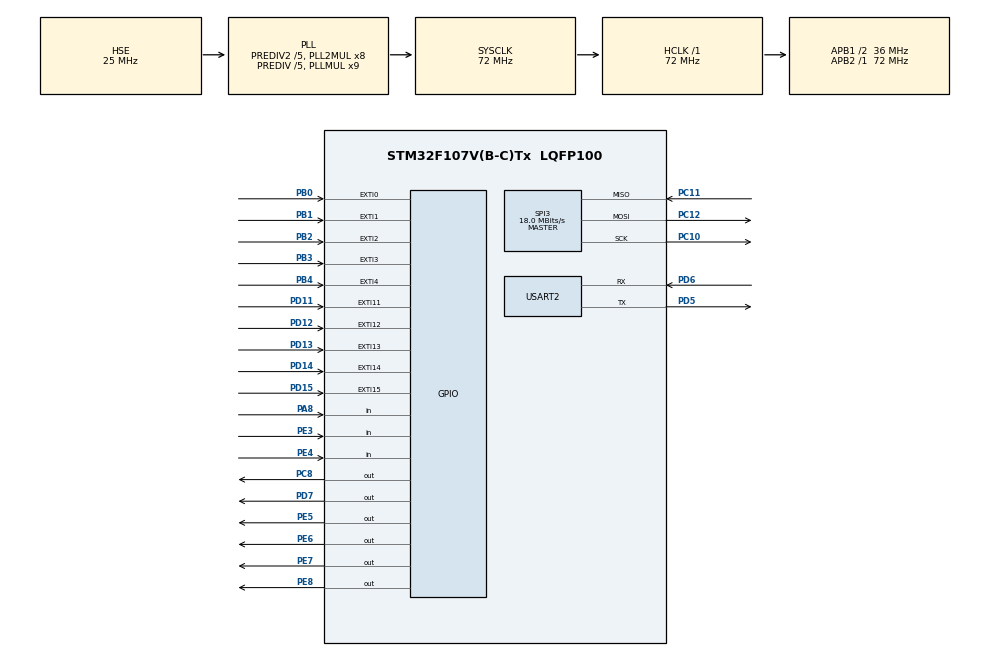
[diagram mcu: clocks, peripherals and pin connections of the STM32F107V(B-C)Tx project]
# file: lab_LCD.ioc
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Mcu.Family=STM32F1
Mcu.Name=STM32F107V(B-C)Tx
Mcu.Package=LQFP100
NVIC.EXTI0_IRQn=true\:0\:0\:false\:false\:true
NVIC.EXTI15_10_IRQn=true\:2\:0\:true\:false\:true
NVIC.EXTI1_IRQn=true\:0\:0\:false\:false\:true
NVIC.EXTI2_IRQn=true\:0\:0\:false\:false\:true
NVIC.EXTI3_IRQn=true\:0\:0\:false\:false\:true
NVIC.EXTI4_IRQn=true\:0\:0\:false\:false\:true
NVIC.PriorityGroup=NVIC_PRIORITYGROUP_2
NVIC.SPI3_IRQn=true\:2\:2\:true\:false\:true
NVIC.TIM1_UP_IRQn=true\:1\:0\:true\:false\:true
OSC_IN.Mode=HSE-External-Oscillator
OSC_IN.Signal=RCC_OSC_IN
OSC_OUT.Mode=HSE-External-Oscillator
OSC_OUT.Signal=RCC_OSC_OUT
PA8.Signal=GPIO_Input
PB0.Signal=GPXTI0
PB1.Signal=GPXTI1
PB2.Signal=GPXTI2
PB3.Signal=GPXTI3
PB4.Signal=GPXTI4
PC10.Mode=Full_Duplex_Master
PC10.Signal=SPI3_SCK
PC11.Mode=Full_Duplex_Master
PC11.Signal=SPI3_MISO
PC12.Mode=Full_Duplex_Master
PC12.Signal=SPI3_MOSI
PC8.Signal=GPIO_Output
PD11.Signal=GPXTI11
PD12.Signal=GPXTI12
PD13.Signal=GPXTI13
PD14.Signal=GPXTI14
PD15.Signal=GPXTI15
PD5.Mode=Asynchronous
PD5.Signal=USART2_TX
PD6.Mode=Asynchronous
PD6.Signal=USART2_RX
PD7.Signal=GPIO_Output
PE3.Signal=GPIO_Input
PE4.Signal=GPIO_Input
PE5.Signal=GPIO_Output
PE6.Signal=GPIO_Output
PE7.Signal=GPIO_Output
PE8.Signal=GPIO_Output
ProjectManager.HeapSize=0x200
ProjectManager.StackSize=0x400
ProjectManager.TargetToolchain=MDK-ARM V5
RCC.AHBFreq_Value=72000000
RCC.APB1CLKDivider=RCC_HCLK_DIV2
RCC.APB1Freq_Value=36000000
RCC.APB1TimFreq_Value=72000000
RCC.APB2Freq_Value=72000000
RCC.APB2TimFreq_Value=72000000
RCC.HCLKFreq_Value=72000000
RCC.HSEDivPLL=RCC_HSE_PREDIV_DIV5
RCC.HSE_VALUE=25000000
RCC.HSIState=RCC_HSI_ON
RCC.PLLMUL=RCC_PLL_MUL9
RCC.PLLSourceVirtual=RCC_PLLSOURCE_HSE
RCC.Prediv1Source=RCC_PREDIV1_SOURCE_PLL2
RCC.Prediv2=RCC_HSE_PREDIV2_DIV5
RCC.SYSCLKFreq_VALUE=72000000
RCC.SYSCLKSource=RCC_SYSCLKSOURCE_PLLCLK
RCC.USBFreq_Value=48000000
SPI3.CLKPhase=SPI_PHASE_1EDGE
SPI3.CLKPolarity=SPI_POLARITY_LOW
SPI3.CalculateBaudRate=18.0 MBits/s
SPI3.Mode=SPI_MODE_MASTER
VP_SYS_VS_ND.Mode=No_Debug
VP_TIM1_VS_ClockSourceINT.Mode=Internal
VP_TIM2_VS_ClockSourceINT.Mode=Internal
board=lab_LCD

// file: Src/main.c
/**
  ******************************************************************************
  * File Name          : main.c
  * Description        : Main program body
  ******************************************************************************
  *
  * COPYRIGHT(c) 2018 STMicroelectronics
  *
  * Redistribution and use in source and binary forms, with or without modification,
  * are permitted provided that the following conditions are met:
  *   1. Redistributions of source code must retain the above copyright notice,
  *      this list of conditions and the following disclaimer.
  *   2. Redistributions in binary form must reproduce the above copyright notice,
  *      this list of conditions and the following disclaimer in the documentation
  *      and/or other materials provided with the distribution.
  *   3. Neither the name of STMicroelectronics nor the names of its contributors
  *      may be used to endorse or promote products derived from this software
  *      without specific prior written permission.
  *
  * THIS SOFTWARE IS PROVIDED BY THE COPYRIGHT HOLDERS AND CONTRIBUTORS "AS IS"
  * AND ANY EXPRESS OR IMPLIED WARRANTIES, INCLUDING, BUT NOT LIMITED TO, THE
  * IMPLIED WARRANTIES OF MERCHANTABILITY AND FITNESS FOR A PARTICULAR PURPOSE ARE
  * DISCLAIMED. IN NO EVENT SHALL THE COPYRIGHT HOLDER OR CONTRIBUTORS BE LIABLE
  * FOR ANY DIRECT, INDIRECT, INCIDENTAL, SPECIAL, EXEMPLARY, OR CONSEQUENTIAL
  * DAMAGES (INCLUDING, BUT NOT LIMITED TO, PROCUREMENT OF SUBSTITUTE GOODS OR
  * SERVICES; LOSS OF USE, DATA, OR PROFITS; OR BUSINESS INTERRUPTION) HOWEVER
  * CAUSED AND ON ANY THEORY OF LIABILITY, WHETHER IN CONTRACT, STRICT LIABILITY,
  * OR TORT (INCLUDING NEGLIGENCE OR OTHERWISE) ARISING IN ANY WAY OUT OF THE USE
  * OF THIS SOFTWARE, EVEN IF ADVISED OF THE POSSIBILITY OF SUCH DAMAGE.
  *
  ******************************************************************************
  */
#include "main.h"
#include "stm32f1xx_hal.h"

/* USER CODE BEGIN Includes */

#include "et_stm32f_arm_kit_lcd.h"
#include <string.h>
#include <stdlib.h>
#include <time.h>
#include <stdbool.h>

/* USER CODE END Includes */

SPI_HandleTypeDef hspi3;

TIM_HandleTypeDef htim1;
TIM_HandleTypeDef htim2;

UART_HandleTypeDef huart2;

/* USER CODE BEGIN PV */
/* Private variables ---------------------------------------------------------*/
uint8_t posX;
uint16_t posY;
uint16_t i=10;
uint32_t count;
uint32_t sec;
uint32_t min;
uint16_t hue[20];

int isPress[5] = {0,0,0,0,0};
int score = 0;
int state = 0 ;
// state 0 : title
// state 1 : wait for Button Press
// state 2 : prerender background
// state 3 : gameplay
// state 4 : clear screen
// state 5 : gameover
int isDrawTitle = 0;
uint32_t timeshow[5] = {0,0,0,0,0};
uint32_t gametime = 59;
uint32_t temptimeshow[5] = {0,0,0,0,0};
int locationMole[3] = {0,1,2};
bool locationAvailable[5] = {false,false,false,false,false};
uint8_t locationX[5]= {80,80,160,160,160};
uint16_t locationY[5] = {109,218,80,160,240};
int mole[5] ={0,0,0};
char str[20];
/* USER CODE END PV */

void SystemClock_Config(void);
void Error_Handler(void);
static void MX_GPIO_Init(void);
static void MX_SPI3_Init(void);
static void MX_USART2_UART_Init(void);
static void MX_TIM2_Init(void);
static void MX_TIM1_Init(void);

/* USER CODE BEGIN PFP */
/* Private function prototypes -----------------------------------------------*/

char pos[50];
uint32_t count;
uint32_t sec;
uint32_t min;
uint16_t fox[13][15] = {
    {0xFFFF,0xFFFF,0xFFFF,0x0000,0xFFFF,0xFFFF,0xFFFF,0xFFFF,0xFFFF,0xFFFF,0xFFFF,0x0000,0xFFFF,0xFFFF,0xFFFF},
    {0xFFFF,0xFFFF,0x0000,0xFFFF,0x0000,0xFFFF,0xFFFF,0xFFFF,0xFFFF,0xFFFF,0x0000,0xFFFF,0x0000,0xFFFF,0xFFFF},
  	{0xFFFF,0xFFFF,0x0000,0xFFFF,0xF3C0,0x0000,0xFFFF,0xFFFF,0xFFFF,0x0000,0xF3C0,0xFFFF,0x0000,0xFFFF,0xFFFF},
		{0xFFFF,0xFFFF,0x0000,0xFFFF,0xF3C0,0xF3C0,0x0000,0x0000,0x0000,0xF3C0,0xF3C0,0xFFFF,0x0000,0xFFFF,0xFFFF},
		{0xFFFF,0xFFFF,0x0000,0xFFFF,0x0000,0x0000,0xF3C0,0xF3C0,0xF3C0,0x0000,0x0000,0xFFFF,0x0000,0xFFFF,0xFFFF},
		{0xFFFF,0xFFFF,0x0000,0x0000,0xF3C0,0xF3C0,0xF3C0,0xF3C0,0xF3C0,0xF3C0,0xF3C0,0x0000,0x0000,0xFFFF,0xFFFF},
		{0xFFFF,0xFFFF,0x0000,0xF3C0,0xF3C0,0xF3C0,0xF3C0,0xF3C0,0xF3C0,0xF3C0,0xF3C0,0xF3C0,0x0000,0xFFFF,0xFFFF},
		{0xFFFF,0xFFFF,0x0000,0xF3C0,0x0000,0xF3C0,0xF3C0,0xF3C0,0xF3C0,0xF3C0,0x0000,0xF3C0,0x0000,0xFFFF,0xFFFF},
		{0xFFFF,0x0000,0xF3C0,0xF3C0,0x0000,0xF3C0,0x0000,0x0000,0x0000,0xF3C0,0x0000,0xF3C0,0xF3C0,0x0000,0xFFFF},
		{0xFFFF,0x0000,0xF3C0,0xF3C0,0xF3C0,0xF3C0,0xFFFF,0x0000,0xFFFF,0xF3C0,0xF3C0,0xF3C0,0xF3C0,0x0000,0xFFFF},
		{0x0000,0xF3C0,0xF3C0,0xF3C0,0xF3C0,0xFFFF,0xFFFF,0xFFFF,0xFFFF,0xFFFF,0xF3C0,0xF3C0,0xF3C0,0xF3C0,0x0000},
		{0xFFFF,0x0000,0x0000,0xFFFF,0xFFFF,0xFFFF,0xFFFF,0xFFFF,0xFFFF,0xFFFF,0xFFFF,0xFFFF,0x0000,0x0000,0xFFFF},
	  {0xFFFF,0xFFFF,0xFFFF,0x0000,0x0000,0x0000,0x0000,0x0000,0x0000,0x0000,0x0000,0x0000,0xFFFF,0xFFFF,0xFFFF}
};

uint16_t molepic[15][15] = {
    { 0x6223,0x0000,0x0000,0x0000,0x0000,0x0000,0x0000,0x0000,0x0000,0x0000,0x0000,0x0000,0x0000,0x0000,0x6223 },
    { 0x0000,0xBBEB,0x0000,0x0000,0x0000,0xBBEB,0xBBEB,0xBBEB,0xBBEB,0xBBEB,0x0000,0x0000,0x0000,0xBBEB,0x0000 },
    { 0x0000,0x0000,0x0000,0xBBEB,0xBBEB,0xBBEB,0xBBEB,0xBBEB,0xBBEB,0xBBEB,0xBBEB,0xBBEB,0x0000,0x0000,0x0000 },
    { 0x0000,0x0000,0xBBEB,0xBBEB,0xBBEB,0xBBEB,0xBBEB,0xBBEB,0xBBEB,0xBBEB,0xBBEB,0xBBEB,0xBBEB,0x0000,0x0000 },
    { 0x0000,0x0000,0xBBEB,0xBBEB,0xBBEB,0xBBEB,0xBBEB,0xBBEB,0xBBEB,0xBBEB,0xBBEB,0xBBEB,0xBBEB,0x0000,0x0000 },
    { 0x0000,0xBBEB,0x0000,0xBBEB,0xBBEB,0xBBEB,0xBBEB,0xBBEB,0xBBEB,0xBBEB,0xBBEB,0xBBEB,0x0000,0xBBEB,0x0000 },
    { 0x0000,0xBBEB,0x0000,0x0000,0xBBEB,0xBBEB,0x0000,0x0000,0x0000,0xBBEB,0xBBEB,0x0000,0x0000,0xBBEB,0x0000 },
    { 0x0000,0xBBEB,0xBBEB,0xBBEB,0xBBEB,0xBBEB,0xBBEB,0x0000,0xBBEB,0xBBEB,0xBBEB,0xBBEB,0xBBEB,0xBBEB,0x0000 },
    { 0x0000,0xBBEB,0xBBEB,0xBBEB,0xBBEB,0xBBEB,0x0000,0xBBEB,0x0000,0xBBEB,0xBBEB,0xBBEB,0xBBEB,0xBBEB,0x0000 },
    { 0x0000,0xBBEB,0xBBEB,0xBBEB,0xBBEB,0x0000,0xBBEB,0xBBEB,0xBBEB,0x0000,0xBBEB,0xBBEB,0xBBEB,0xBBEB,0x0000 },
    { 0x0000,0x0000,0xBBEB,0xBBEB,0xBBEB,0xBBEB,0xBBEB,0xBBEB,0xBBEB,0xBBEB,0xBBEB,0xBBEB,0xBBEB,0x0000,0x0000 },
    { 0x0000,0x0000,0xBBEB,0xBBEB,0xBBEB,0xBBEB,0x0000,0x0000,0x0000,0xBBEB,0xBBEB,0xBBEB,0xBBEB,0x0000,0x0000 },
    { 0x0000,0x0000,0x0000,0xBBEB,0xBBEB,0x0000,0xE5F2,0xE5F2,0xE5F2,0x0000,0xBBEB,0xBBEB,0x0000,0x0000,0x0000 },
    { 0x0000,0x0000,0xBBEB,0x0000,0x0000,0xE5F2,0xE5F2,0xE5F2,0xE5F2,0xE5F2,0x0000,0x0000,0xBBEB,0x0000,0x0000 },
    { 0x6223,0x0000,0x0000,0x0000,0x0000,0x0000,0x0000,0x0000,0x0000,0x0000,0x0000,0x0000,0x0000,0x0000,0x6223 }  };
uint16_t title[16][32] ={
	{0x0000, 0x0000, 0x0000, 0x0000, 0x0000, 0x0000, 0x0000, 0x0000, 0x0000, 0x0000, 0x0000, 0x0000, 0x0000, 0x0000, 0x0000, 0x0000, 0x0000, 0x0000, 0x0000, 0x0000, 0x0000, 0x0000, 0x0000, 0x0000, 0x0000, 0x0000, 0x0000, 0x0000, 0x0000, 0x0000, 0x0000, 0x0000},
	{0x0000, 0x0000, 0x0000, 0x0000, 0x0000, 0x0000, 0x0000, 0x0000, 0x0000, 0x0000, 0x0000, 0x0000, 0x0000, 0x0000, 0x0000, 0x0000, 0x0000, 0x0000, 0x0000, 0x0000, 0x0000, 0x0000, 0x0000, 0x0000, 0x0000, 0x0000, 0x0000, 0x0000, 0x0000, 0x0000, 0x0000, 0x0000},
	{0x0000, 0x0000, 0x0000, 0x0000, 0x0000, 0x0000, 0x0000, 0x0000, 0x7205, 0x0000, 0x0000, 0x0000, 0x7205, 0x0000, 0xFC26, 0x0000, 0x0000, 0xFC26, 0x0000, 0x7205, 0x7205, 0x7205, 0x7205, 0x0000, 0xFC26, 0xFC26, 0xFC26, 0xFC26, 0x0000, 0x0000, 0x0000, 0x0000},
	{0x0000, 0x0000, 0x0000, 0x0000, 0x0000, 0x0000, 0x0000, 0x0000, 0x7205, 0x0000, 0x0000, 0x0000, 0x7205, 0x0000, 0xFC26, 0x0000, 0x0000, 0xFC26, 0x0000, 0x7205, 0x0000, 0x0000, 0x7205, 0x0000, 0xFC26, 0x0000, 0x0000,  0xFC26, 0x0000, 0x0000, 0x0000, 0x0000},
	{0x0000, 0x0000, 0x0000, 0x0000, 0x0000, 0x0000, 0x0000, 0x0000, 0x7205, 0x0000, 0x7205, 0x0000, 0x7205, 0x0000, 0xFC26, 0xFC26, 0xFC26, 0xFC26, 0x0000, 0x7205, 0x7205,  0x7205, 0x7205, 0x0000, 0xFC26, 0x0000, 0x0000,0x0000, 0x0000, 0x0000, 0x0000, 0x0000},
	{0x0000, 0x0000, 0x0000, 0x0000, 0xFFFF, 0xFFFF, 0x0000, 0x0000, 0x7205, 0x7205, 0x7205, 0x7205, 0x7205, 0x0000, 0xFC26, 0x0000, 0x0000, 0xFC26, 0x0000, 0x7205, 0x0000, 0x0000, 0x7205, 0x0000, 0xFC26, 0x0000, 0x0000, 0xFC26, 0x0000, 0x0000, 0x0000, 0x0000},
	{0x0000, 0x0000, 0x0000, 0xFFFF, 0x0000, 0x0000, 0xFFFF, 0x0000, 0x7205, 0x7205, 0x0000, 0x7205, 0x7205, 0x0000, 0xFC26, 0x0000, 0x0000, 0x0000, 0x0000, 0x0000, 0x0000, 0x0000, 0x7205, 0x0000, 0xFC26, 0xFC26, 0xFC26, 0xFC26, 0x0000, 0x0000, 0x0000, 0x0000},
	{0x0000, 0x0000, 0x0000, 0xFFFF, 0xFFFF, 0xFFFF, 0xFFFF, 0x0000, 0x0000, 0x0000, 0x0000, 0x0000, 0x0000, 0x0000, 0xBBEB, 0x0000, 0x0000, 0x0000, 0x0000, 0x0000, 0xBBEB, 0x0000, 0x7205, 0x0000, 0x0000, 0x0000, 0x0000, 0x0000, 0x0000, 0x0000, 0x0000, 0x0000},
	{0x0000, 0x0000, 0x0000, 0xFFFF, 0x0000, 0x0000, 0xFFFF, 0x0000, 0xFE22, 0xFE22, 0x0000, 0xFE22, 0xFE22, 0x0000, 0x0000, 0xBBEB, 0xBBEB, 0xBBEB, 0xBBEB, 0xBBEB, 0x0000, 0x0000, 0x7205, 0x0000, 0x0000, 0x7205, 0x7205, 0x7205, 0x0000, 0x0000, 0x0000, 0x0000},
	{0x0000, 0x0000, 0x0000, 0x0000, 0x0000, 0x0000, 0x0000, 0x0000, 0xFE22, 0xFE22, 0x0000, 0xFE22, 0xFE22, 0x0000, 0xBBEB, 0xBBEB, 0xBBEB, 0xBBEB, 0xBBEB, 0xBBEB, 0xBBEB, 0x0000, 0x7205, 0x0000, 0x0000, 0x7205, 0x0000, 0x0000, 0x0000, 0x0000, 0x0000, 0x0000},
  {0x0000, 0x0000, 0x0000, 0x0000, 0x0000, 0x0000, 0x0000, 0x0000, 0xFE22, 0x0000, 0xFE22, 0x0000, 0xFE22, 0x0000, 0xBBEB, 0xBBEB, 0xBBEB, 0xBBEB, 0xBBEB, 0xBBEB, 0xBBEB, 0x0000, 0x7205, 0x0000, 0x0000, 0x7205, 0x7205, 0x7205, 0x0000, 0x0000, 0x0000, 0x0000},
	{0x0000, 0x0000, 0x0000, 0x0000, 0x0000, 0x0000, 0x0000, 0x0000, 0xFE22, 0x0000, 0x0000, 0x0000, 0xFE22, 0x0000, 0xBBEB, 0x0000, 0xBBEB, 0xBBEB, 0xBBEB, 0x0000, 0xBBEB, 0x0000, 0x7205, 0x0000, 0x0000, 0x7205, 0x0000, 0x0000, 0x0000, 0x0000, 0x0000, 0x0000},
	{0x0000, 0x0000, 0x0000, 0x0000, 0x0000, 0x0000, 0x0000, 0x0000, 0xFE22, 0x0000, 0x0000, 0x0000, 0xFE22, 0x0000, 0xBBEB, 0xBBEB, 0xBBEB, 0xBBEB, 0xBBEB, 0xBBEB, 0xBBEB, 0x0000, 0x7205, 0x7205, 0x7205, 0x7205, 0x7205, 0x7205, 0x0000, 0x0000, 0x0000, 0x0000},
	{0x0000, 0x0000, 0x0000, 0x0000, 0x0000, 0x0000, 0x0000, 0x0000, 0x0000, 0x0000, 0x0000, 0x0000, 0x0000, 0x0000, 0xBBEB, 0xBBEB, 0xBBEB, 0x0000, 0xBBEB, 0xBBEB, 0xBBEB, 0x0000, 0x0000, 0x0000, 0x0000, 0x0000, 0x0000, 0x0000, 0x0000, 0x0000, 0x0000, 0x0000},
  {0x0000, 0x0000, 0x0000, 0x0000, 0x0000, 0x0000, 0x0000, 0x0000, 0x0000, 0x0000, 0x0000, 0x0000, 0x0000, 0x0000, 0x0000, 0xBBEB, 0x0000, 0xE5F2, 0x0000, 0xBBEB, 0x0000, 0x0000, 0x0000, 0x0000, 0x0000, 0x0000, 0x0000, 0x0000, 0x0000, 0x0000, 0x0000, 0x0000},
	{0x0000, 0x0000, 0x0000, 0x0000, 0x0000, 0x0000, 0x0000, 0x0000, 0x0000, 0x0000, 0x0000, 0x0000, 0x0000, 0x0000, 0xBBEB, 0x0000, 0x0000, 0x0000, 0x0000, 0x0000, 0xBBEB, 0x0000, 0x0000, 0x0000, 0x0000, 0x0000, 0x0000, 0x0000, 0x0000, 0x0000, 0x0000, 0x0000},

};
uint16_t moleDie[15][15] = {
{0x0000, 0x0000, 0x0000, 0x0000, 0x0000, 0xFFFF, 0xFFFF, 0x0000, 0xFFFF, 0xFFFF, 0x0000, 0x0000, 0x0000, 0x0000, 0x0000},
{0x0000, 0xBBEB, 0x0000, 0x0000, 0x0000, 0xBBEB, 0xFFFF, 0xFFFF, 0xFFFF, 0xBBEB, 0x0000, 0x0000, 0x0000, 0xBBEB, 0x0000},
{0x0000, 0x0000, 0x0000, 0xBBEB, 0xBBEB, 0xBBEB, 0xBBEB, 0xFFFF, 0xBBEB, 0xBBEB, 0xBBEB, 0xBBEB, 0x0000, 0x0000, 0x0000},
{0x0000, 0x0000, 0xBBEB, 0xBBEB, 0xBBEB, 0xBBEB, 0xFFFF, 0xFFFF, 0xFFFF, 0xBBEB, 0xBBEB, 0xBBEB, 0xBBEB, 0x0000, 0x0000},
{0x0000, 0x0000, 0xBBEB, 0xBBEB, 0xBBEB, 0xFFFF, 0xFFFF, 0xBBEB, 0xFFFF, 0xFFFF, 0xBBEB, 0xBBEB, 0xBBEB, 0x0000, 0x0000},
{0x0000, 0xBBEB, 0x0000, 0xBBEB, 0x0000, 0xBBEB, 0xBBEB, 0xBBEB, 0xBBEB, 0xBBEB, 0x0000, 0xBBEB, 0x0000, 0xBBEB, 0x0000},
{0x0000, 0xBBEB, 0xBBEB, 0x0000, 0xBBEB, 0xBBEB, 0x0000, 0x0000, 0x0000, 0xBBEB, 0xBBEB, 0x0000, 0xBBEB, 0xBBEB, 0x0000},
{0x0000, 0xBBEB, 0x0000, 0x46DF, 0x0000, 0xBBEB, 0xBBEB, 0x0000, 0xBBEB, 0xBBEB, 0x0000, 0x46DF, 0x0000, 0xBBEB, 0x0000},
{0x0000, 0xBBEB, 0xBBEB, 0x46DF, 0xBBEB, 0xBBEB, 0x0000, 0xF57F, 0x0000, 0xBBEB, 0xBBEB, 0x46DF, 0xBBEB, 0xBBEB, 0x0000},
{0x0000, 0xBBEB, 0xBBEB, 0x46DF, 0xBBEB, 0xBBEB, 0x0000, 0x0000, 0x0000, 0xBBEB, 0xBBEB, 0x46DF, 0xBBEB, 0xBBEB, 0x0000},
{0x0000, 0x0000, 0xBBEB, 0x46DF, 0xBBEB, 0xBBEB, 0xBBEB, 0xBBEB, 0xBBEB, 0xBBEB, 0xBBEB, 0x46DF, 0xBBEB, 0x0000, 0x0000},
{0x0000, 0x0000, 0xBBEB, 0x46DF, 0xBBEB, 0xBBEB, 0x0000, 0x0000, 0x0000, 0xBBEB, 0xBBEB, 0x46DF, 0xBBEB, 0x0000, 0x0000},
{0x0000, 0xBBEB, 0x0000, 0x46DF, 0xBBEB, 0x0000, 0xE5F2, 0xE5F2, 0xE5F2, 0x0000, 0xBBEB, 0x46DF, 0x0000, 0xBBEB, 0x0000},
{0x0000, 0x0000, 0x0000, 0x0000, 0x0000, 0xE5F2, 0xE5F2, 0xE5F2, 0xE5F2, 0xE5F2, 0x0000, 0x0000, 0x0000, 0x0000, 0x0000},
{0x0000, 0x0000, 0x0000, 0x0000, 0x0000, 0x0000, 0x0000, 0x0000, 0x0000, 0x0000, 0x0000, 0x0000, 0x0000, 0x0000, 0x0000}
};

uint16_t background[48][64] = {
{0x6223,0x6223, 0x6223,0x6223, 0x6223,0x6223, 0x6223,0x6223, 0x6223,0x6223, 0x6223,0x6223, 0x6223,0x6223, 0x6223,0x6223, 0x6223,0x6223, 0x6223,0x6223, 0x6223,0x6223, 0x6223,0x6223, 0x6223,0x6223, 0x6223,0x6223, 0x6223,0x6223, 0x6223,0x6223, 0x6223,0x6223, 0x6223,0x6223, 0x6223,0x6223, 0x6223,0x6223, 0x6223,0x6223, 0x6223,0x6223, 0x6223,0x6223, 0x6223,0x6223, 0x6223,0x6223, 0x6223,0x6223, 0x6223,0x6223, 0x6223,0x6223, 0x6223,0xB668, 0xB668,0x6223, 0x6223,0x6223, 0xB668,0xB668},
{0x6223,0x6223, 0x6223,0x6223, 0x6223,0x6223, 0x6223,0xB668, 0xB668,0x6223, 0x6223,0x6223, 0x6223,0x6223, 0xB668,0x6223, 0x6223,0x6223, 0x6223,0x8327, 0x6223,0x6223, 0x6223,0x6223, 0x6223,0x6223, 0x6223,0x6223, 0x6223,0x6223, 0x6223,0x6223, 0x6223,0x6223, 0x6223,0x6223, 0x6223,0x6223, 0x6223,0x6223, 0x6223,0x6223, 0x6223,0x6223, 0x6223,0x6223, 0x6223,0x6223, 0x6223,0x6223, 0x6223,0x6223, 0x6223,0x6223, 0x6223,0x6223, 0x6223,0xB668, 0xB668,0xB668, 0xB668,0xB668, 0xB668,0x6223},
{0x6223,0x6223, 0x6223,0x6223, 0x6223,0x6223, 0x6223,0xB668, 0xB668,0xB668, 0x6223,0x6223, 0x6223,0xB668, 0xB668,0x6223, 0x6223,0x6223, 0x6223,0x6223, 0x6223,0x6223, 0x6223,0x6223, 0x6223,0x6223, 0x6223,0x6223, 0x6223,0x6223, 0x6223,0x6223, 0x6223,0x6223, 0x6223,0x6223, 0x6223,0x6223, 0x6223,0x6223, 0x6223,0x6223, 0x6223,0x6223, 0x6223,0x6223, 0x6223,0x6223, 0x6223,0x6223, 0x6223,0x6223, 0x6223,0x6223, 0x6223,0x6223, 0x6223,0x6223, 0x6223,0x6223, 0xB668,0x6223, 0x6223,0x6223},
{0x6223,0x8327, 0x6223,0x6223, 0x6223,0x6223, 0x6223,0x6223, 0x6223,0xB668, 0xB668,0xB668, 0xB668,0xB668, 0x6223,0x6223, 0x6223,0x6223, 0x6223,0x6223, 0x6223,0x6223, 0x6223,0x6223, 0x6223,0x6223, 0x6223,0x6223, 0x6223,0x6223, 0x6223,0x6223, 0x6223,0x6223, 0x6223,0x6223, 0x6223,0x6223, 0x6223,0x6223, 0x6223,0x6223, 0x6223,0x6223, 0x6223,0x6223, 0x8327,0x6223, 0x6223,0x6223, 0x6223,0x6223, 0x6223,0x6223, 0x6223,0x6223, 0x6223,0x6223, 0x6223,0x6223, 0x6223,0x6223, 0x6223,0x6223},
{0x6223,0x6223, 0x6223,0x6223, 0x6223,0x6223, 0x6223,0x6223, 0x6223,0x6223, 0xB668,0xB668, 0x6223,0x6223, 0x6223,0x6223, 0x6223,0x6223, 0x6223,0x6223, 0x6223,0x6223, 0x6223,0x6223, 0x6223,0x6223, 0x6223,0x6223, 0x6223,0x6223, 0x6223,0x6223, 0x6223,0x6223, 0x6223,0x6223, 0x6223,0x6223, 0x6223,0x6223, 0x6223,0x6223, 0x6223,0x6223, 0x6223,0x6223, 0x6223,0x6223, 0x6223,0x6223, 0x6223,0x6223, 0x6223,0x6223, 0x6223,0x6223, 0x6223,0x6223, 0x6223,0x6223, 0x6223,0x6223, 0x6223,0x6223},
{0x6223,0x6223, 0x6223,0x6223, 0x6223,0x6223, 0x6223,0x6223, 0x6223,0x6223, 0x6223,0x6223, 0x6223,0x6223, 0x6223,0x6223, 0x6223,0x6223, 0x6223,0x6223, 0x6223,0x6223, 0x6223,0x6223, 0x6223,0x6223, 0x6223,0x6223, 0x6223,0x6223, 0x6223,0x6223, 0x6223,0x6223, 0x6223,0x6223, 0x6223,0x6223, 0x6223,0x6223, 0x6223,0x6223, 0x6223,0x6223, 0x6223,0x6223, 0x6223,0x6223, 0x6223,0x6223, 0x6223,0x6223, 0x6223,0x6223, 0x6223,0x6223, 0x6223,0x6223, 0x6223,0x6223, 0x6223,0x6223, 0x6223,0x6223},
{0x6223,0x6223, 0x6223,0x6223, 0x6223,0x6223, 0x6223,0x6223, 0x6223,0x6223, 0x6223,0x6223, 0x6223,0x6223, 0x6223,0x6223, 0x6223,0x6223, 0x6223,0x6223, 0x6223,0x6223, 0x6223,0x6223, 0x6223,0x6223, 0x6223,0x6223, 0x6223,0x6223, 0x6223,0x6223, 0x6223,0x6223, 0x6223,0x6223, 0x6223,0x6223, 0x6223,0x6223, 0x6223,0x6223, 0x6223,0x6223, 0x6223,0x6223, 0x6223,0x6223, 0x6223,0x6223, 0x6223,0x6223, 0x6223,0x6223, 0x6223,0x6223, 0x6223,0x6223, 0x6223,0x6223, 0x6223,0x6223, 0x6223,0x6223},
{0x6223,0x6223, 0x6223,0x6223, 0x6223,0x6223, 0x6223,0x6223, 0x6223,0x6223, 0x6223,0x6223, 0x6223,0x6223, 0x6223,0x6223, 0x6223,0x6223, 0x6223,0x6223, 0x6223,0x6223, 0x6223,0x6223, 0x6223,0x6223, 0x6223,0x6223, 0x6223,0x6223, 0x6223,0x6223, 0x6223,0x6223, 0x6223,0x6223, 0x6223,0x6223, 0x6223,0x6223, 0x6223,0x6223, 0x6223,0x6223, 0x6223,0x6223, 0x6223,0x6223, 0x6223,0x6223, 0x6223,0x6223, 0x6223,0x6223, 0x6223,0x6223, 0x6223,0x6223, 0x6223,0x6223, 0x6223,0x6223, 0x6223,0x6223},
{0x6223,0x6223, 0x6223,0x6223, 0x6223,0x6223, 0x6223,0x6223, 0x6223,0x6223, 0x6223,0x6223, 0x6223,0x6223, 0x6223,0x6223, 0x8327,0x6223, 0x6223,0x6223, 0x6223,0x6223, 0x6223,0x6223, 0x6223,0x6223, 0x6223,0x6223, 0x6223,0x6223, 0x6223,0x6223, 0x6223,0x6223, 0x6223,0x6223, 0x6223,0x6223, 0x6223,0x6223, 0x6223,0x6223, 0x6223,0x6223, 0x6223,0x6223, 0x6223,0x6223, 0x6223,0x6223, 0x6223,0x6223, 0x6223,0x6223, 0x6223,0x6223, 0x6223,0x6223, 0x6223,0x6223, 0x6223,0x6223, 0x6223,0x6223},
{0x6223,0x6223, 0x6223,0x6223, 0x6223,0x6223, 0x6223,0x6223, 0x6223,0x6223, 0x6223,0x6223, 0x6223,0x6223, 0x6223,0x6223, 0x6223,0x6223, 0x6223,0x6223, 0x6223,0x6223, 0x6223,0x6223, 0x6223,0x6223, 0x6223,0x6223, 0x6223,0x6223, 0x6223,0x6223, 0x6223,0x6223, 0x6223,0x6223, 0x6223,0x6223, 0x6223,0x6223, 0x6223,0x6223, 0x6223,0x6223, 0x6223,0x6223, 0x6223,0x6223, 0x6223,0x6223, 0x6223,0x6223, 0x6223,0x6223, 0x6223,0x6223, 0x6223,0x6223, 0x6223,0x6223, 0x6223,0x6223, 0x6223,0x6223},
{0x6223,0x6223, 0x6223,0x6223, 0x6223,0x6223, 0x6223,0x6223, 0x6223,0x6223, 0x6223,0x6223, 0x6223,0x6223, 0x6223,0x6223, 0x6223,0x6223, 0x6223,0x6223, 0x6223,0x6223, 0x6223,0x6223, 0x6223,0x6223, 0x6223,0x6223, 0x6223,0x6223, 0x6223,0x6223, 0x6223,0x6223, 0x6223,0x6223, 0x6223,0x6223, 0x6223,0x6223, 0x6223,0x6223, 0x6223,0x6223, 0x6223,0x6223, 0x6223,0x6223, 0x8327,0x6223, 0x6223,0x6223, 0x6223,0x6223, 0x6223,0x6223, 0x6223,0x6223, 0x6223,0x6223, 0x6223,0x6223, 0x6223,0x6223},
{0x6223,0x6223, 0x8327,0x6223, 0x6223,0x6223, 0x6223,0x6223, 0x6223,0x6223, 0x6223,0x6223, 0x6223,0x6223, 0x6223,0x6223, 0x6223,0x6223, 0x6223,0x6223, 0x6223,0x6223, 0x6223,0x6223, 0x6223,0x6223, 0x6223,0x6223, 0x6223,0x6223, 0x6223,0x6223, 0x6223,0x6223, 0x6223,0x6223, 0x6223,0x6223, 0x6223,0x6223, 0x6223,0x6223, 0x6223,0x6223, 0x6223,0x6223, 0x6223,0x6223, 0x6223,0x6223, 0x6223,0x6223, 0x6223,0x6223, 0x6223,0x6223, 0x6223,0x6223, 0x6223,0x6223, 0x6223,0x6223, 0x6223,0x6223},
{0x6223,0x6223, 0x6223,0x6223, 0x6223,0x6223, 0x6223,0x6223, 0x6223,0x6223, 0x6223,0x6223, 0x6223,0x6223, 0x6223,0x6223, 0x6223,0x6223, 0x6223,0x6223, 0x6223,0x6223, 0x6223,0x6223, 0x6223,0x6223, 0x6223,0x6223, 0x6223,0x6223, 0x6223,0x6223, 0x6223,0x6223, 0x6223,0x6223, 0x6223,0x6223, 0x6223,0x6223, 0x6223,0x6223, 0x6223,0x6223, 0x6223,0x6223, 0x6223,0x6223, 0x6223,0x6223, 0x6223,0x6223, 0x6223,0x6223, 0x6223,0x6223, 0x6223,0x6223, 0x6223,0x6223, 0x6223,0x6223, 0x6223,0x6223},
{0x6223,0x6223, 0x6223,0x6223, 0x6223,0x6223, 0x6223,0x6223, 0x6223,0x6223, 0x6223,0x6223, 0x6223,0x6223, 0x6223,0x6223, 0x6223,0x6223, 0x6223,0x6223, 0x6223,0x6223, 0x6223,0x6223, 0x6223,0x6223, 0x6223,0x6223, 0x6223,0x6223, 0x6223,0x6223, 0x6223,0x6223, 0x6223,0x6223, 0x6223,0x8327, 0x6223,0x6223, 0x6223,0x6223, 0x6223,0x6223, 0x6223,0x6223, 0x6223,0x6223, 0x6223,0x6223, 0x6223,0x6223, 0x6223,0x6223, 0x6223,0x6223, 0x6223,0x6223, 0x6223,0x6223, 0x6223,0x6223, 0x6223,0x6223},
{0x6223,0x6223, 0x6223,0x6223, 0x6223,0x6223, 0x6223,0x6223, 0x6223,0x6223, 0x6223,0x6223, 0x6223,0x6223, 0x6223,0x6223, 0x6223,0x6223, 0x6223,0x6223, 0x6223,0x6223, 0x6223,0x6223, 0x6223,0x6223, 0x6223,0x6223, 0x6223,0x6223, 0x6223,0x6223, 0x6223,0x6223, 0x6223,0x6223, 0x6223,0x6223, 0x6223,0x6223, 0x6223,0x6223, 0x6223,0x6223, 0x6223,0x6223, 0x6223,0x6223, 0x6223,0x6223, 0x6223,0x6223, 0x6223,0x6223, 0x6223,0x6223, 0x6223,0x6223, 0x6223,0x6223, 0x6223,0x6223, 0x6223,0x6223},
{0x6223,0x6223, 0x6223,0x6223, 0x6223,0x6223, 0x6223,0x6223, 0x6223,0x6223, 0x6223,0x6223, 0x6223,0x6223, 0x6223,0x6223, 0x6223,0x6223, 0x6223,0x6223, 0x6223,0x6223, 0x6223,0x6223, 0x6223,0x6223, 0x6223,0x6223, 0x6223,0x6223, 0x6223,0x6223, 0x6223,0x6223, 0x6223,0x6223, 0x6223,0x6223, 0x6223,0x6223, 0x6223,0x6223, 0x8327,0x6223, 0x6223,0x6223, 0x6223,0x6223, 0x6223,0x6223, 0x6223,0x6223, 0x6223,0x6223, 0xB668,0xB668, 0x6223,0x6223, 0x6223,0xB668, 0xB668,0x6223, 0x6223,0x6223},
{0x6223,0x6223, 0x6223,0x6223, 0x6223,0x6223, 0x6223,0x6223, 0x6223,0x6223, 0x6223,0x6223, 0x6223,0x6223, 0x6223,0x6223, 0x6223,0x6223, 0x6223,0x6223, 0x6223,0x6223, 0x6223,0x6223, 0x6223,0x6223, 0x6223,0x6223, 0x6223,0x6223, 0x6223,0x6223, 0x6223,0x6223, 0x6223,0x6223, 0x6223,0x6223, 0x6223,0x6223, 0x6223,0x6223, 0x6223,0x6223, 0x6223,0x6223, 0x6223,0x6223, 0x6223,0x6223, 0x6223,0x6223, 0x6223,0x6223, 0x6223,0xB668, 0xB668,0xB668, 0xB668,0xB668, 0xB668,0x6223, 0x6223,0x6223},
{0x6223,0x6223, 0x6223,0x6223, 0x6223,0x6223, 0x6223,0x6223, 0x6223,0x6223, 0x6223,0x6223, 0x6223,0x6223, 0x6223,0x6223, 0x6223,0x6223, 0x6223,0x6223, 0x6223,0x6223, 0x6223,0x6223, 0x6223,0x6223, 0x6223,0x6223, 0x6223,0x6223, 0x6223,0x6223, 0x6223,0x6223, 0x6223,0x6223, 0x6223,0x6223, 0x6223,0x6223, 0x6223,0x6223, 0x6223,0x6223, 0x6223,0x6223, 0x6223,0x6223, 0x6223,0x6223, 0x6223,0x6223, 0x6223,0x6223, 0x6223,0x6223, 0x6223,0xB668, 0xB668,0x6223, 0x6223,0x6223, 0x6223,0x6223},
{0x6223,0x6223, 0x6223,0x6223, 0x6223,0x6223, 0x6223,0x6223, 0x6223,0x6223, 0x6223,0x6223, 0x6223,0x6223, 0x6223,0x6223, 0x6223,0x6223, 0x6223,0x6223, 0x6223,0x6223, 0x6223,0x6223, 0x6223,0x6223, 0x6223,0x6223, 0x6223,0x6223, 0x6223,0x6223, 0x6223,0x6223, 0x6223,0x6223, 0x6223,0x6223, 0x6223,0x6223, 0x6223,0x6223, 0x6223,0x6223, 0x6223,0x6223, 0x6223,0x6223, 0x6223,0x6223, 0x6223,0x6223, 0x6223,0x6223, 0x6223,0x6223, 0x6223,0x6223, 0x6223,0x6223, 0x6223,0x6223, 0x6223,0x6223},
{0x6223,0x6223, 0x6223,0x6223, 0x6223,0x6223, 0x6223,0x6223, 0x6223,0x6223, 0x6223,0x6223, 0x6223,0x6223, 0x6223,0x6223, 0x6223,0x6223, 0x6223,0x6223, 0x6223,0x6223, 0x6223,0x6223, 0x6223,0x6223, 0x6223,0x6223, 0x6223,0x6223, 0x6223,0x6223, 0x6223,0x6223, 0x6223,0x6223, 0x6223,0x6223, 0x6223,0x6223, 0x6223,0x6223, 0x6223,0x6223, 0x6223,0x6223, 0x6223,0x6223, 0x6223,0x6223, 0x6223,0x6223, 0x6223,0x6223, 0x6223,0x6223, 0x6223,0x6223, 0x6223,0x6223, 0x6223,0x6223, 0x6223,0x6223},
{0x6223,0x6223, 0x6223,0x6223, 0x6223,0x6223, 0x6223,0x6223, 0x6223,0x6223, 0x6223,0x6223, 0x6223,0x6223, 0x6223,0x6223, 0x6223,0x6223, 0x6223,0x6223, 0x6223,0x6223, 0x6223,0x6223, 0x6223,0x6223, 0x6223,0x6223, 0x6223,0x6223, 0x6223,0x6223, 0x6223,0x6223, 0x6223,0x6223, 0x6223,0x6223, 0x6223,0x6223, 0x6223,0x6223, 0x6223,0x6223, 0x6223,0x6223, 0x6223,0x6223, 0x6223,0x6223, 0x6223,0x6223, 0x6223,0x6223, 0x6223,0x6223, 0x6223,0x6223, 0x6223,0x6223, 0x6223,0x6223, 0x6223,0x6223},
{0x6223,0x6223, 0x6223,0x6223, 0x6223,0x6223, 0x6223,0x6223, 0x6223,0x6223, 0x6223,0x6223, 0x6223,0x6223, 0x6223,0x6223, 0x6223,0x6223, 0x6223,0x6223, 0x6223,0x6223, 0x6223,0x6223, 0x6223,0x6223, 0x6223,0x6223, 0x6223,0x6223, 0x6223,0x6223, 0x6223,0x6223, 0x6223,0x6223, 0x6223,0x6223, 0x6223,0x6223, 0x6223,0x6223, 0x6223,0x6223, 0x6223,0x6223, 0x6223,0x6223, 0x6223,0x6223, 0x6223,0x6223, 0x6223,0x6223, 0x6223,0x6223, 0x6223,0x6223, 0x6223,0x6223, 0x6223,0x6223, 0x6223,0x6223},
{0x6223,0x6223, 0x6223,0x6223, 0x6223,0x6223, 0x6223,0x6223, 0x6223,0x6223, 0x6223,0x6223, 0x6223,0x6223, 0x6223,0x6223, 0x6223,0x6223, 0x6223,0x6223, 0x6223,0x6223, 0x6223,0x6223, 0x6223,0x6223, 0x6223,0x6223, 0x6223,0x6223, 0x6223,0x6223, 0x6223,0x6223, 0x6223,0x6223, 0x6223,0x6223, 0x6223,0x6223, 0x6223,0x6223, 0x6223,0x6223, 0x6223,0x6223, 0x6223,0x6223, 0x6223,0x8327, 0x6223,0x6223, 0x6223,0x6223, 0x6223,0x6223, 0x6223,0x6223, 0x6223,0x6223, 0x6223,0x6223, 0x6223,0x6223},
{0x6223,0x6223, 0x6223,0x6223, 0x6223,0x6223, 0x6223,0x6223, 0x6223,0x6223, 0x6223,0x6223, 0x6223,0x6223, 0x6223,0x6223, 0x6223,0x6223, 0x6223,0x6223, 0x6223,0x6223, 0x6223,0x6223, 0x6223,0x6223, 0x6223,0x6223, 0x6223,0x6223, 0x6223,0x6223, 0x6223,0x6223, 0x6223,0x6223, 0x6223,0x6223, 0x6223,0x6223, 0x6223,0x6223, 0x6223,0x6223, 0x6223,0x6223, 0x6223,0x6223, 0x6223,0x6223, 0x6223,0x6223, 0x6223,0x6223, 0x6223,0x6223, 0x6223,0x6223, 0x6223,0x6223, 0x6223,0x6223, 0x6223,0x6223},
{0x6223,0x6223, 0x6223,0x6223, 0x6223,0x6223, 0x6223,0x6223, 0x6223,0x6223, 0x6223,0x6223, 0x6223,0x6223, 0x6223,0x6223, 0x6223,0x6223, 0x6223,0x6223, 0x6223,0x6223, 0x6223,0x6223, 0x6223,0x6223, 0x6223,0x6223, 0x6223,0x6223, 0x6223,0x6223, 0x6223,0x6223, 0x6223,0x6223, 0x6223,0x6223, 0x6223,0x6223, 0x6223,0x6223, 0x6223,0x6223, 0x6223,0x6223, 0x6223,0x6223, 0x6223,0x6223, 0x6223,0x6223, 0x6223,0x6223, 0x6223,0x6223, 0x6223,0x6223, 0x6223,0x6223, 0x6223,0x6223, 0x6223,0x6223},
{0x6223,0x6223, 0x8327,0x6223, 0x6223,0x6223, 0x6223,0x6223, 0x6223,0x6223, 0x6223,0x6223, 0x6223,0x6223, 0x6223,0x6223, 0x6223,0x6223, 0x6223,0x6223, 0x6223,0x6223, 0x6223,0x6223, 0x6223,0x6223, 0x6223,0x6223, 0x6223,0x6223, 0x6223,0x6223, 0x6223,0x6223, 0x6223,0x6223, 0x6223,0x6223, 0x6223,0x6223, 0x6223,0x6223, 0x6223,0x6223, 0x6223,0x6223, 0x6223,0x6223, 0x6223,0x6223, 0x6223,0x6223, 0x6223,0x6223, 0x6223,0x6223, 0x6223,0x6223, 0x6223,0x6223, 0x6223,0x6223, 0x6223,0x6223},
{0x6223,0x6223, 0x6223,0x6223, 0x6223,0x6223, 0x6223,0x6223, 0x6223,0x6223, 0x6223,0x6223, 0x6223,0x6223, 0x6223,0x6223, 0x6223,0x6223, 0x6223,0x6223, 0x6223,0x6223, 0x6223,0x6223, 0x6223,0x6223, 0x6223,0x6223, 0x6223,0x6223, 0x6223,0x6223, 0x6223,0x6223, 0x6223,0x6223, 0x6223,0x6223, 0x6223,0x6223, 0x6223,0x6223, 0x6223,0x6223, 0x6223,0x6223, 0x6223,0x6223, 0x6223,0x6223, 0x6223,0x6223, 0x6223,0x6223, 0x6223,0x6223, 0x6223,0x6223, 0x6223,0x6223, 0x6223,0x8327, 0x6223,0x6223},
{0x6223,0x6223, 0x6223,0x6223, 0x6223,0x6223, 0x6223,0x6223, 0x6223,0x6223, 0x6223,0x6223, 0x6223,0x6223, 0x6223,0x6223, 0x6223,0x6223, 0x6223,0x6223, 0x6223,0x6223, 0x6223,0x6223, 0x6223,0x6223, 0x6223,0x6223, 0x6223,0x6223, 0x6223,0x6223, 0x6223,0x6223, 0x6223,0x6223, 0x6223,0x6223, 0x6223,0x6223, 0x6223,0x6223, 0x6223,0x6223, 0x6223,0x6223, 0x6223,0x6223, 0x6223,0x6223, 0x6223,0x6223, 0x6223,0x6223, 0x6223,0x6223, 0x6223,0x6223, 0x6223,0x6223, 0x6223,0x6223, 0x6223,0x6223},
{0x6223,0x6223, 0x6223,0x6223, 0x6223,0x6223, 0x6223,0x6223, 0x6223,0x6223, 0x6223,0x6223, 0x6223,0x6223, 0x6223,0x6223, 0x6223,0x6223, 0x6223,0x6223, 0x6223,0x6223, 0x6223,0x6223, 0x6223,0x6223, 0x6223,0x6223, 0x6223,0x6223, 0x6223,0x6223, 0x6223,0x6223, 0x6223,0x6223, 0x6223,0x6223, 0x6223,0x6223, 0x6223,0x6223, 0x6223,0x6223, 0x6223,0x6223, 0x6223,0x6223, 0x6223,0x6223, 0x6223,0x6223, 0x6223,0x6223, 0x6223,0x6223, 0x6223,0x6223, 0x6223,0x6223, 0x6223,0x6223, 0x6223,0x6223},
{0x6223,0x6223, 0x6223,0x6223, 0x6223,0x6223, 0x6223,0x6223, 0x6223,0x6223, 0x6223,0x6223, 0x6223,0x6223, 0x6223,0x6223, 0x6223,0x6223, 0x6223,0x6223, 0x6223,0x6223, 0x6223,0x6223, 0x6223,0x6223, 0x6223,0x6223, 0x6223,0x6223, 0x6223,0x6223, 0x6223,0x6223, 0x6223,0x6223, 0x6223,0x6223, 0x6223,0x6223, 0x6223,0x6223, 0x6223,0x6223, 0x6223,0x6223, 0x6223,0x6223, 0x6223,0x6223, 0x6223,0x6223, 0x6223,0x6223, 0x6223,0x6223, 0x6223,0x6223, 0x6223,0x6223, 0x6223,0x6223, 0x6223,0x6223},
{0x6223,0x6223, 0x6223,0x6223, 0x6223,0x6223, 0x6223,0x6223, 0x6223,0x6223, 0x6223,0x6223, 0x6223,0x6223, 0x6223,0x6223, 0x6223,0x6223, 0x6223,0x6223, 0x6223,0x6223, 0x6223,0x6223, 0x6223,0x6223, 0x6223,0x6223, 0x6223,0x6223, 0x6223,0x6223, 0x6223,0x6223, 0x6223,0x6223, 0x6223,0x6223, 0x6223,0x6223, 0x6223,0x6223, 0x6223,0x6223, 0x6223,0x6223, 0x6223,0x6223, 0x6223,0x6223, 0x6223,0x6223, 0x6223,0x6223, 0x6223,0x6223, 0x6223,0x6223, 0x6223,0x6223, 0x6223,0x6223, 0x6223,0x6223},
{0x6223,0x6223, 0xB668,0xB668, 0xB668,0x6223, 0x6223,0x6223, 0x6223,0xB668, 0xB668,0x6223, 0x6223,0x6223, 0x6223,0x6223, 0x6223,0x6223, 0x6223,0x6223, 0x6223,0x6223, 0x6223,0x6223, 0x6223,0x6223, 0x6223,0x6223, 0x6223,0x6223, 0x6223,0x6223, 0x6223,0x6223, 0x6223,0x6223, 0x6223,0x6223, 0x6223,0x6223, 0x6223,0x6223, 0x6223,0x6223, 0x6223,0x6223, 0x6223,0x6223, 0x6223,0x6223, 0x6223,0x6223, 0x6223,0x6223, 0x6223,0x6223, 0x6223,0x6223, 0x6223,0x6223, 0x6223,0x6223, 0x6223,0x6223},
{0x6223,0x6223, 0x6223,0xB668, 0xB668,0xB668, 0x6223,0xB668, 0xB668,0xB668, 0xB668,0x6223, 0x6223,0x6223, 0x6223,0x6223, 0x6223,0x6223, 0x6223,0x6223, 0x6223,0x6223, 0x6223,0x6223, 0x6223,0x6223, 0x6223,0x6223, 0x6223,0x6223, 0x6223,0x6223, 0x6223,0x6223, 0x6223,0x6223, 0x6223,0x6223, 0x6223,0x6223, 0x6223,0x6223, 0x6223,0x6223, 0x6223,0x6223, 0x6223,0x6223, 0x6223,0x6223, 0x6223,0x6223, 0x6223,0x6223, 0x6223,0x6223, 0x6223,0x6223, 0x6223,0x6223, 0x6223,0x6223, 0x6223,0x6223},
{0x6223,0x6223, 0x6223,0x6223, 0x6223,0xB668, 0xB668,0xB668, 0xB668,0x6223, 0x6223,0x6223, 0x6223,0x6223, 0x6223,0x6223, 0x6223,0x6223, 0x6223,0x6223, 0x6223,0x6223, 0x6223,0x6223, 0x6223,0x6223, 0x6223,0x6223, 0x6223,0x6223, 0x6223,0x6223, 0x6223,0x6223, 0x6223,0x6223, 0x6223,0x6223, 0x6223,0x6223, 0x6223,0x6223, 0x6223,0x6223, 0x6223,0x6223, 0x6223,0x6223, 0x6223,0x6223, 0x6223,0x6223, 0x6223,0x6223, 0x6223,0x6223, 0x6223,0x6223, 0x6223,0x6223, 0x6223,0x6223, 0x6223,0x6223},
{0x6223,0x6223, 0x6223,0x6223, 0x6223,0x6223, 0x6223,0x6223, 0x6223,0x6223, 0x6223,0x6223, 0x6223,0x6223, 0x6223,0x6223, 0x6223,0x6223, 0x6223,0x6223, 0x6223,0x6223, 0x6223,0x6223, 0x6223,0x6223, 0x6223,0x6223, 0x6223,0x6223, 0x6223,0x6223, 0x6223,0x6223, 0x6223,0x6223, 0x6223,0x6223, 0x6223,0x8327, 0x6223,0x6223, 0x6223,0x6223, 0x6223,0x6223, 0x6223,0x6223, 0x6223,0x6223, 0x6223,0x6223, 0x6223,0x6223, 0x6223,0x6223, 0x6223,0x6223, 0x6223,0x6223, 0x6223,0x6223, 0x6223,0x6223},
{0x6223,0x6223, 0x6223,0x6223, 0x6223,0x6223, 0x6223,0x6223, 0x6223,0x6223, 0x6223,0x6223, 0x6223,0x6223, 0x6223,0x6223, 0x6223,0x6223, 0x6223,0x6223, 0x6223,0x6223, 0x6223,0x6223, 0x6223,0x6223, 0x6223,0x6223, 0x6223,0x8327, 0x6223,0x6223, 0x6223,0x6223, 0x6223,0x6223, 0x6223,0x6223, 0x6223,0x6223, 0x6223,0x6223, 0x6223,0x6223, 0x6223,0x6223, 0x6223,0x6223, 0x6223,0x6223, 0x6223,0x6223, 0x6223,0x6223, 0x6223,0x6223, 0x6223,0x6223, 0x6223,0x6223, 0x6223,0x6223, 0x6223,0x6223},
{0x6223,0x6223, 0x6223,0x6223, 0x6223,0x6223, 0x6223,0x6223, 0x6223,0x6223, 0x6223,0x6223, 0x6223,0x6223, 0x6223,0x6223, 0x6223,0x6223, 0x6223,0x6223, 0x6223,0x6223, 0x6223,0x6223, 0x6223,0x6223, 0x6223,0x6223, 0x6223,0x6223, 0x6223,0x6223, 0x6223,0x6223, 0x6223,0x6223, 0x6223,0x6223, 0x6223,0x6223, 0x6223,0x6223, 0x6223,0x6223, 0x6223,0x6223, 0x6223,0x6223, 0x6223,0x6223, 0x6223,0x6223, 0x6223,0x6223, 0x6223,0x6223, 0x6223,0x6223, 0x6223,0x6223, 0x6223,0x6223, 0x6223,0x6223},
{0x6223,0x6223, 0x6223,0x6223, 0x6223,0x6223, 0x6223,0x6223, 0x6223,0x6223, 0x6223,0x6223, 0x6223,0x6223, 0x6223,0x6223, 0x6223,0x6223, 0x6223,0x6223, 0x6223,0x6223, 0x6223,0x6223, 0x6223,0x6223, 0x6223,0x6223, 0x6223,0x6223, 0x6223,0x6223, 0x6223,0x6223, 0x6223,0x6223, 0x6223,0x6223, 0x6223,0x6223, 0x6223,0x6223, 0x6223,0x6223, 0x6223,0x6223, 0x6223,0x6223, 0x6223,0x6223, 0x6223,0x6223, 0x6223,0x6223, 0x6223,0x6223, 0x6223,0x6223, 0x6223,0x6223, 0x6223,0x6223, 0x6223,0x6223},
{0x6223,0x6223, 0x6223,0x6223, 0x6223,0x6223, 0x6223,0x6223, 0x6223,0x6223, 0x6223,0x6223, 0x6223,0x6223, 0x6223,0x6223, 0x6223,0x6223, 0x6223,0x6223, 0x6223,0x6223, 0x6223,0x6223, 0x6223,0x6223, 0x6223,0x6223, 0x6223,0x6223, 0x6223,0x6223, 0x6223,0x6223, 0x6223,0x6223, 0x6223,0x6223, 0x6223,0x6223, 0x6223,0x6223, 0x6223,0x6223, 0x6223,0x6223, 0x6223,0x6223, 0x6223,0x6223, 0x6223,0x6223, 0x6223,0x6223, 0x6223,0x6223, 0x6223,0x6223, 0x6223,0x6223, 0x6223,0x6223, 0x6223,0x6223},
{0x6223,0x6223, 0x6223,0x6223, 0x6223,0x6223, 0x6223,0x6223, 0x6223,0x6223, 0x6223,0x6223, 0x6223,0x6223, 0x6223,0x6223, 0x6223,0x6223, 0x6223,0x6223, 0x6223,0x6223, 0x6223,0x6223, 0x6223,0x6223, 0x6223,0x6223, 0x6223,0x6223, 0x6223,0x6223, 0x6223,0x6223, 0x6223,0x6223, 0x6223,0x6223, 0x6223,0x6223, 0x6223,0x6223, 0x6223,0x6223, 0x6223,0x6223, 0x6223,0x6223, 0x6223,0x6223, 0x6223,0x6223, 0x6223,0x6223, 0x6223,0x6223, 0x6223,0x6223, 0x6223,0x6223, 0x6223,0x6223, 0x6223,0x6223},
{0x6223,0x6223, 0x6223,0x6223, 0x6223,0x6223, 0x6223,0x6223, 0x6223,0x6223, 0x6223,0x6223, 0x6223,0x6223, 0x6223,0x6223, 0x6223,0x6223, 0x6223,0x6223, 0x6223,0x6223, 0x6223,0x6223, 0x6223,0x6223, 0x6223,0x6223, 0x6223,0x6223, 0x6223,0x6223, 0x6223,0x6223, 0x6223,0x6223, 0x6223,0x6223, 0x6223,0x6223, 0x6223,0x6223, 0x6223,0x8327, 0x6223,0x6223, 0x6223,0x6223, 0x6223,0x6223, 0x6223,0x6223, 0x6223,0x6223, 0x6223,0x6223, 0x6223,0x6223, 0x6223,0x6223, 0x6223,0x6223, 0x6223,0x6223},
{0x6223,0x6223, 0x6223,0x6223, 0x6223,0x6223, 0x6223,0x6223, 0x6223,0x6223, 0x6223,0x6223, 0x6223,0x6223, 0x6223,0x6223, 0x6223,0x6223, 0x6223,0x6223, 0x6223,0x6223, 0x6223,0x6223, 0x6223,0x6223, 0x6223,0x6223, 0x6223,0x6223, 0x6223,0x6223, 0x6223,0x6223, 0x6223,0x6223, 0x6223,0x6223, 0x6223,0x6223, 0x6223,0x6223, 0x6223,0x6223, 0x6223,0x6223, 0x6223,0x6223, 0x6223,0x6223, 0x6223,0x6223, 0x6223,0x6223, 0x6223,0x6223, 0x6223,0x6223, 0x6223,0x6223, 0x6223,0x6223, 0x6223,0x6223},
{0x6223,0x6223, 0x6223,0x6223, 0x6223,0x6223, 0x6223,0x6223, 0x6223,0x6223, 0x6223,0x6223, 0x6223,0x6223, 0x6223,0x6223, 0x6223,0x6223, 0x6223,0x6223, 0x6223,0x6223, 0x6223,0x6223, 0x6223,0x6223, 0x6223,0x6223, 0x6223,0x6223, 0x6223,0x6223, 0x6223,0x6223, 0x6223,0x6223, 0x6223,0x6223, 0x6223,0x6223, 0x6223,0x6223, 0x6223,0x6223, 0x6223,0x6223, 0x6223,0x6223, 0x6223,0x6223, 0x6223,0x6223, 0x6223,0x6223, 0x6223,0x6223, 0x6223,0x6223, 0x6223,0x6223, 0x6223,0x6223, 0x6223,0x6223},
{0x6223,0x6223, 0x6223,0x6223, 0x6223,0x6223, 0x6223,0x6223, 0x6223,0x6223, 0x6223,0x6223, 0x6223,0x6223, 0x6223,0x6223, 0x6223,0x6223, 0x6223,0x6223, 0x6223,0x6223, 0x6223,0x6223, 0x6223,0x6223, 0x6223,0x6223, 0x6223,0x6223, 0x6223,0x6223, 0x6223,0x6223, 0x8327,0x6223, 0x6223,0x6223, 0x6223,0x6223, 0x6223,0x6223, 0x6223,0x6223, 0x6223,0x6223, 0x6223,0x6223, 0x6223,0x6223, 0x6223,0x6223, 0x6223,0x6223, 0x6223,0x6223, 0x6223,0x6223, 0x6223,0x6223, 0x6223,0x6223, 0x6223,0x6223},
{0x6223,0x6223, 0x6223,0x6223, 0x6223,0x6223, 0x6223,0x6223, 0x6223,0x6223, 0x6223,0x6223, 0x6223,0x6223, 0x6223,0x6223, 0x6223,0x6223, 0x6223,0x6223, 0x6223,0x6223, 0x6223,0x6223, 0x6223,0x6223, 0x6223,0x6223, 0x6223,0x6223, 0x6223,0x6223, 0x6223,0x6223, 0x6223,0x6223, 0x6223,0x6223, 0x6223,0x6223, 0x6223,0x6223, 0x6223,0x6223, 0x6223,0x6223, 0x6223,0x6223, 0x6223,0x6223, 0x6223,0x6223, 0x6223,0x6223, 0x6223,0x6223, 0x6223,0x6223, 0x6223,0x6223, 0x6223,0x6223, 0x6223,0x6223},
{0x6223,0x6223, 0x6223,0x6223, 0x6223,0x6223, 0x6223,0x6223, 0x6223,0x6223, 0x6223,0x6223, 0x6223,0x6223, 0x6223,0x6223, 0x6223,0x6223, 0x6223,0x6223, 0x6223,0x6223, 0x6223,0x6223, 0x6223,0x6223, 0x6223,0x6223, 0x6223,0x6223, 0x6223,0x6223, 0x6223,0x6223, 0x8327,0x6223, 0x6223,0x6223, 0x6223,0x6223, 0x6223,0x6223, 0x6223,0x6223, 0x6223,0x6223, 0x6223,0x6223, 0x6223,0x6223, 0x6223,0x6223, 0x6223,0x6223, 0x6223,0x6223, 0x6223,0x6223, 0x6223,0x6223, 0x6223,0x6223, 0x6223,0x6223},
{0x6223,0x6223, 0x6223,0x6223, 0x6223,0x6223, 0x6223,0x6223, 0x6223,0x6223, 0x6223,0x6223, 0x6223,0x6223, 0x6223,0x6223, 0x6223,0x6223, 0x6223,0x6223, 0x6223,0x6223, 0x6223,0x6223, 0x6223,0x6223, 0x6223,0x6223, 0x6223,0x6223, 0x6223,0x6223, 0x6223,0x6223, 0x6223,0x6223, 0x6223,0x6223, 0x6223,0x6223, 0x6223,0x6223, 0x6223,0x6223, 0x6223,0x6223, 0x6223,0x6223, 0x6223,0x6223, 0x6223,0x6223, 0x6223,0x6223, 0x6223,0x6223, 0x6223,0x6223, 0x6223,0x6223, 0x6223,0x6223, 0x6223,0x6223},
{0x6223,0x6223, 0x6223,0x6223, 0x6223,0x6223, 0x6223,0x6223, 0x6223,0x6223, 0x6223,0x6223, 0x6223,0x6223, 0x6223,0x6223, 0x6223,0x6223, 0x6223,0x6223, 0x6223,0x6223, 0x6223,0x6223, 0x6223,0x6223, 0x6223,0x6223, 0x6223,0x6223, 0x6223,0x6223, 0x6223,0x6223, 0x6223,0x6223, 0x6223,0x6223, 0x6223,0x6223, 0x6223,0x6223, 0x6223,0x6223, 0x6223,0x6223, 0x6223,0x6223, 0x6223,0x6223, 0x6223,0x6223, 0x6223,0x6223, 0x6223,0x6223, 0x6223,0x6223, 0x6223,0x6223, 0x6223,0x6223, 0x6223,0x6223}
};

uint16_t hole[19][19] = {
{ 0x6223, 0x6223, 0x6223, 0x6223, 0x6223, 0x6223, 0x0000, 0x0000, 0x0000, 0x0000, 0x0000, 0x0000, 0x0000, 0x6223, 0x6223, 0x6223, 0x6223, 0x6223, 0x6223 },
{ 0x6223, 0x6223, 0x6223, 0x6223, 0x0000, 0x0000, 0x0000, 0x0000, 0x0000, 0x0000, 0x0000, 0x0000, 0x0000, 0x0000, 0x0000, 0x6223, 0x6223, 0x6223, 0x6223 },
{ 0x6223, 0x6223, 0x6223, 0x0000, 0x0000, 0x0000, 0x0000, 0x0000, 0x0000, 0x0000, 0x0000, 0x0000, 0x0000, 0x0000, 0x0000, 0x0000, 0x6223, 0x6223, 0x6223 },
{ 0x6223, 0x6223, 0x0000, 0x0000, 0x0000, 0x0000, 0x0000, 0x0000, 0x0000, 0x0000, 0x0000, 0x0000, 0x0000, 0x0000, 0x0000, 0x0000, 0x0000, 0x6223, 0x6223 },
{ 0x6223, 0x0000, 0x0000, 0x0000, 0x0000, 0x0000, 0x0000, 0x0000, 0x0000, 0x0000, 0x0000, 0x0000, 0x0000, 0x0000, 0x0000, 0x0000, 0x0000, 0x0000, 0x6223 },
{ 0x6223, 0x0000, 0x0000, 0x0000, 0x0000, 0x0000, 0x0000, 0x0000, 0x0000, 0x0000, 0x0000, 0x0000, 0x0000, 0x0000, 0x0000, 0x0000, 0x0000, 0x0000, 0x6223 },
{ 0x0000, 0x0000, 0x0000, 0x0000, 0x0000, 0x0000, 0x0000, 0x0000, 0x0000, 0x0000, 0x0000, 0x0000, 0x0000, 0x0000, 0x0000, 0x0000, 0x0000, 0x0000, 0x0000},
{ 0x0000, 0x0000, 0x0000, 0x0000, 0x0000, 0x0000, 0x0000, 0x0000, 0x0000, 0x0000, 0x0000, 0x0000, 0x0000, 0x0000, 0x0000, 0x0000, 0x0000, 0x0000, 0x0000},
{ 0x0000, 0x0000, 0x0000, 0x0000, 0x0000, 0x0000, 0x0000, 0x0000, 0x0000, 0x0000, 0x0000, 0x0000, 0x0000, 0x0000, 0x0000, 0x0000, 0x0000, 0x0000, 0x0000},
{ 0x0000, 0x0000, 0x0000, 0x0000, 0x0000, 0x0000, 0x0000, 0x0000, 0x0000, 0x0000, 0x0000, 0x0000, 0x0000, 0x0000, 0x0000, 0x0000, 0x0000, 0x0000, 0x0000},
{ 0x0000, 0x0000, 0x0000, 0x0000, 0x0000, 0x0000, 0x0000, 0x0000, 0x0000, 0x0000, 0x0000, 0x0000, 0x0000, 0x0000, 0x0000, 0x0000, 0x0000, 0x0000, 0x0000},
{ 0x0000, 0x0000, 0x0000, 0x0000, 0x0000, 0x0000, 0x0000, 0x0000, 0x0000, 0x0000, 0x0000, 0x0000, 0x0000, 0x0000, 0x0000, 0x0000, 0x0000, 0x0000, 0x0000},
{ 0x0000, 0x0000, 0x0000, 0x0000, 0x0000, 0x0000, 0x0000, 0x0000, 0x0000, 0x0000, 0x0000, 0x0000, 0x0000, 0x0000, 0x0000, 0x0000, 0x0000, 0x0000, 0x0000},
{ 0x6223, 0x0000, 0x0000, 0x0000, 0x0000, 0x0000, 0x0000, 0x0000, 0x0000, 0x0000, 0x0000, 0x0000, 0x0000, 0x0000, 0x0000, 0x0000, 0x0000, 0x0000, 0x6223},
{ 0x6223, 0x0000, 0x0000, 0x0000, 0x0000, 0x0000, 0x0000, 0x0000, 0x0000, 0x0000, 0x0000, 0x0000, 0x0000, 0x0000, 0x0000, 0x0000, 0x0000, 0x0000, 0x6223},
{ 0x6223, 0x6223, 0x0000, 0x0000, 0x0000, 0x0000, 0x0000, 0x0000, 0x0000, 0x0000, 0x0000, 0x0000, 0x0000, 0x0000, 0x0000, 0x0000, 0x0000, 0x6223, 0x6223},
{ 0x6223, 0x6223, 0x6223, 0x0000, 0x0000, 0x0000, 0x0000, 0x0000, 0x0000, 0x0000, 0x0000, 0x0000, 0x0000, 0x0000, 0x0000, 0x0000, 0x6223, 0x6223, 0x6223},
{ 0x6223, 0x6223, 0x6223, 0x6223, 0x0000, 0x0000, 0x0000, 0x0000, 0x0000, 0x0000, 0x0000, 0x0000, 0x0000, 0x0000, 0x0000, 0x6223, 0x6223, 0x6223, 0x6223},
{ 0x6223, 0x6223, 0x6223, 0x6223, 0x6223, 0x6223, 0x0000, 0x0000, 0x0000, 0x0000, 0x0000, 0x0000, 0x0000, 0x6223, 0x6223, 0x6223, 0x6223, 0x6223, 0x6223}
};

/* USER CODE END PFP */

/* USER CODE BEGIN 0 */
static void drawCircle(void);
static void set_map(void);
static void draw_offset(void);
static void gameplay(void);
static void gameover(void);
void control(void);
static void hue_draw(void);
static void hole_init(void);
static void draw_mole(int offsetx, int offsety,uint8_t sizeX,uint16_t sizeY);
static void draw_clear(int offsetx, int offsety,uint8_t sizeX,uint16_t sizeY);
static void draw_title(int offsetx, int offsety,uint8_t sizeX,uint16_t sizeY);
static void draw_moleDie(int offsetx, int offsety,uint8_t sizeX,uint16_t sizeY);
static void draw_background(int offsetx, int offsety,uint8_t sizeX,uint16_t sizeY);
static void draw_hole(int offsetx, int offsety,uint8_t sizeX,uint16_t sizeY);

/* USER CODE END 0 */

int main(void)
{

  /* MCU Configuration----------------------------------------------------------*/

  /* Reset of all peripherals, Initializes the Flash interface and the Systick. */
  HAL_Init();

  /* Configure the system clock */
  SystemClock_Config();

  /* Initialize all configured peripherals */
  MX_GPIO_Init();
  MX_SPI3_Init();
  MX_USART2_UART_Init();
  MX_TIM2_Init();
  MX_TIM1_Init();

  /* USER CODE BEGIN 2 */
	HAL_TIM_Base_Start_IT(&htim1);
	LCD_Setup();
	LCD_SetTextColor(White);
	LCD_SetBackColor(Black);
  //draw_background(0,0,48,64);
	//hole_init();

  /* USER CODE END 2 */

  /* Infinite loop */
  /* USER CODE BEGIN WHILE */
  while (1)
  {
		if(state == 0){

		   draw_title(0,0,16,32);
			 LCD_DisplayStringLine(Line7,"     Prees any key");
			 state = 1 ;
			 LCD_SetTextColor(Black);
	     LCD_SetBackColor(0x6223);
			 gametime = 60;

		}
		if(state == 2 ){

		    draw_background(0,0,48,64);
	      hole_init();
			  state = 3;

		}
		if(state == 3){

			 gameplay();

		}
		if(state == 4 ){

			LCD_Clear(Black);
			state = 5;

		}

		if(state == 5 ){

		  gameover();

		}

  /* USER CODE END WHILE */

	}

}

/** System Clock Configuration
*/
void SystemClock_Config(void)
{

  RCC_OscInitTypeDef RCC_OscInitStruct;
  RCC_ClkInitTypeDef RCC_ClkInitStruct;

    /**Initializes the CPU, AHB and APB busses clocks
    */
  RCC_OscInitStruct.OscillatorType = RCC_OSCILLATORTYPE_HSE;
  RCC_OscInitStruct.HSEState = RCC_HSE_ON;
  RCC_OscInitStruct.HSEPredivValue = RCC_HSE_PREDIV_DIV5;
  RCC_OscInitStruct.HSIState = RCC_HSI_ON;
  RCC_OscInitStruct.Prediv1Source = RCC_PREDIV1_SOURCE_PLL2;
  RCC_OscInitStruct.PLL.PLLState = RCC_PLL_ON;
  RCC_OscInitStruct.PLL.PLLSource = RCC_PLLSOURCE_HSE;
  RCC_OscInitStruct.PLL.PLLMUL = RCC_PLL_MUL9;
  RCC_OscInitStruct.PLL2.PLL2State = RCC_PLL2_ON;
  RCC_OscInitStruct.PLL2.PLL2MUL = RCC_PLL2_MUL8;
  RCC_OscInitStruct.PLL2.HSEPrediv2Value = RCC_HSE_PREDIV2_DIV5;
  if (HAL_RCC_OscConfig(&RCC_OscInitStruct) != HAL_OK)
  {
    Error_Handler();
  }

    /**Initializes the CPU, AHB and APB busses clocks
    */
  RCC_ClkInitStruct.ClockType = RCC_CLOCKTYPE_HCLK|RCC_CLOCKTYPE_SYSCLK
                              |RCC_CLOCKTYPE_PCLK1|RCC_CLOCKTYPE_PCLK2;
  RCC_ClkInitStruct.SYSCLKSource = RCC_SYSCLKSOURCE_PLLCLK;
  RCC_ClkInitStruct.AHBCLKDivider = RCC_SYSCLK_DIV1;
  RCC_ClkInitStruct.APB1CLKDivider = RCC_HCLK_DIV2;
  RCC_ClkInitStruct.APB2CLKDivider = RCC_HCLK_DIV1;

  if (HAL_RCC_ClockConfig(&RCC_ClkInitStruct, FLASH_LATENCY_2) != HAL_OK)
  {
    Error_Handler();
  }

    /**Configure the Systick interrupt time
    */
  HAL_SYSTICK_Config(HAL_RCC_GetHCLKFreq()/1000);

    /**Configure the Systick
    */
  HAL_SYSTICK_CLKSourceConfig(SYSTICK_CLKSOURCE_HCLK);

    /**Configure the Systick interrupt time
    */
  __HAL_RCC_PLLI2S_ENABLE();

  /* SysTick_IRQn interrupt configuration */
  HAL_NVIC_SetPriority(SysTick_IRQn, 0, 0);
}

/* SPI3 init function */
static void MX_SPI3_Init(void)
{

  hspi3.Instance = SPI3;
  hspi3.Init.Mode = SPI_MODE_MASTER;
  hspi3.Init.Direction = SPI_DIRECTION_2LINES;
  hspi3.Init.DataSize = SPI_DATASIZE_8BIT;
  hspi3.Init.CLKPolarity = SPI_POLARITY_LOW;
  hspi3.Init.CLKPhase = SPI_PHASE_1EDGE;
  hspi3.Init.NSS = SPI_NSS_SOFT;
  hspi3.Init.BaudRatePrescaler = SPI_BAUDRATEPRESCALER_2;
  hspi3.Init.FirstBit = SPI_FIRSTBIT_MSB;
  hspi3.Init.TIMode = SPI_TIMODE_DISABLE;
  hspi3.Init.CRCCalculation = SPI_CRCCALCULATION_DISABLE;
  hspi3.Init.CRCPolynomial = 10;
  if (HAL_SPI_Init(&hspi3) != HAL_OK)
  {
    Error_Handler();
  }

}

/* TIM1 init function */
static void MX_TIM1_Init(void)
{

  TIM_ClockConfigTypeDef sClockSourceConfig;
  TIM_MasterConfigTypeDef sMasterConfig;

  htim1.Instance = TIM1;
  htim1.Init.Prescaler = 72-1;
  htim1.Init.CounterMode = TIM_COUNTERMODE_UP;
  htim1.Init.Period = 1000-1;
  htim1.Init.ClockDivision = TIM_CLOCKDIVISION_DIV1;
  htim1.Init.RepetitionCounter = 0;
  if (HAL_TIM_Base_Init(&htim1) != HAL_OK)
  {
    Error_Handler();
  }

  sClockSourceConfig.ClockSource = TIM_CLOCKSOURCE_INTERNAL;
  if (HAL_TIM_ConfigClockSource(&htim1, &sClockSourceConfig) != HAL_OK)
  {
    Error_Handler();
  }

  sMasterConfig.MasterOutputTrigger = TIM_TRGO_RESET;
  sMasterConfig.MasterSlaveMode = TIM_MASTERSLAVEMODE_DISABLE;
  if (HAL_TIMEx_MasterConfigSynchronization(&htim1, &sMasterConfig) != HAL_OK)
  {
    Error_Handler();
  }

}

/* TIM2 init function */
static void MX_TIM2_Init(void)
{

  TIM_ClockConfigTypeDef sClockSourceConfig;
  TIM_MasterConfigTypeDef sMasterConfig;

  htim2.Instance = TIM2;
  htim2.Init.Prescaler = 0;
  htim2.Init.CounterMode = TIM_COUNTERMODE_UP;
  htim2.Init.Period = 0;
  htim2.Init.ClockDivision = TIM_CLOCKDIVISION_DIV1;
  if (HAL_TIM_Base_Init(&htim2) != HAL_OK)
  {
    Error_Handler();
  }

  sClockSourceConfig.ClockSource = TIM_CLOCKSOURCE_INTERNAL;
  if (HAL_TIM_ConfigClockSource(&htim2, &sClockSourceConfig) != HAL_OK)
  {
    Error_Handler();
  }

  sMasterConfig.MasterOutputTrigger = TIM_TRGO_RESET;
  sMasterConfig.MasterSlaveMode = TIM_MASTERSLAVEMODE_DISABLE;
  if (HAL_TIMEx_MasterConfigSynchronization(&htim2, &sMasterConfig) != HAL_OK)
  {
    Error_Handler();
  }

}

/* USART2 init function */
static void MX_USART2_UART_Init(void)
{

  huart2.Instance = USART2;
  huart2.Init.BaudRate = 115200;
  huart2.Init.WordLength = UART_WORDLENGTH_8B;
  huart2.Init.StopBits = UART_STOPBITS_1;
  huart2.Init.Parity = UART_PARITY_NONE;
  huart2.Init.Mode = UART_MODE_TX_RX;
  huart2.Init.HwFlowCtl = UART_HWCONTROL_NONE;
  huart2.Init.OverSampling = UART_OVERSAMPLING_16;
  if (HAL_UART_Init(&huart2) != HAL_OK)
  {
    Error_Handler();
  }

}

/** Configure pins as
        * Analog
        * Input
        * Output
        * EVENT_OUT
        * EXTI
*/
static void MX_GPIO_Init(void)
{

  GPIO_InitTypeDef GPIO_InitStruct;

  /* GPIO Ports Clock Enable */
  __HAL_RCC_GPIOE_CLK_ENABLE();
  __HAL_RCC_GPIOB_CLK_ENABLE();
  __HAL_RCC_GPIOD_CLK_ENABLE();
  __HAL_RCC_GPIOC_CLK_ENABLE();
  __HAL_RCC_GPIOA_CLK_ENABLE();

  /*Configure GPIO pins : PE3 PE4 */
  GPIO_InitStruct.Pin = GPIO_PIN_3|GPIO_PIN_4;
  GPIO_InitStruct.Mode = GPIO_MODE_INPUT;
  GPIO_InitStruct.Pull = GPIO_NOPULL;
  HAL_GPIO_Init(GPIOE, &GPIO_InitStruct);

  /*Configure GPIO pins : PE5 PE6 PE7 PE8 */
  GPIO_InitStruct.Pin = GPIO_PIN_5|GPIO_PIN_6|GPIO_PIN_7|GPIO_PIN_8;
  GPIO_InitStruct.Mode = GPIO_MODE_OUTPUT_PP;
  GPIO_InitStruct.Speed = GPIO_SPEED_FREQ_LOW;
  HAL_GPIO_Init(GPIOE, &GPIO_InitStruct);

  /*Configure GPIO pins : PB0 PB1 PB2 PB3
                           PB4 */
  GPIO_InitStruct.Pin = GPIO_PIN_0|GPIO_PIN_1|GPIO_PIN_2|GPIO_PIN_3
                          |GPIO_PIN_4;
  GPIO_InitStruct.Mode = GPIO_MODE_IT_RISING;
  GPIO_InitStruct.Pull = GPIO_NOPULL;
  HAL_GPIO_Init(GPIOB, &GPIO_InitStruct);

  /*Configure GPIO pins : PD11 PD12 PD13 PD14
                           PD15 */
  GPIO_InitStruct.Pin = GPIO_PIN_11|GPIO_PIN_12|GPIO_PIN_13|GPIO_PIN_14
                          |GPIO_PIN_15;
  GPIO_InitStruct.Mode = GPIO_MODE_IT_RISING;
  GPIO_InitStruct.Pull = GPIO_NOPULL;
  HAL_GPIO_Init(GPIOD, &GPIO_InitStruct);

  /*Configure GPIO pin : PC8 */
  GPIO_InitStruct.Pin = GPIO_PIN_8;
  GPIO_InitStruct.Mode = GPIO_MODE_OUTPUT_PP;
  GPIO_InitStruct.Speed = GPIO_SPEED_FREQ_LOW;
  HAL_GPIO_Init(GPIOC, &GPIO_InitStruct);

  /*Configure GPIO pin : PA8 */
  GPIO_InitStruct.Pin = GPIO_PIN_8;
  GPIO_InitStruct.Mode = GPIO_MODE_INPUT;
  GPIO_InitStruct.Pull = GPIO_NOPULL;
  HAL_GPIO_Init(GPIOA, &GPIO_InitStruct);

  /*Configure GPIO pin : PD7 */
  GPIO_InitStruct.Pin = GPIO_PIN_7;
  GPIO_InitStruct.Mode = GPIO_MODE_OUTPUT_PP;
  GPIO_InitStruct.Speed = GPIO_SPEED_FREQ_LOW;
  HAL_GPIO_Init(GPIOD, &GPIO_InitStruct);

  /*Configure GPIO pin Output Level */
  HAL_GPIO_WritePin(GPIOE, GPIO_PIN_5|GPIO_PIN_6|GPIO_PIN_7|GPIO_PIN_8, GPIO_PIN_RESET);

  /*Configure GPIO pin Output Level */
  HAL_GPIO_WritePin(GPIOC, GPIO_PIN_8, GPIO_PIN_RESET);

  /*Configure GPIO pin Output Level */
  HAL_GPIO_WritePin(GPIOD, GPIO_PIN_7, GPIO_PIN_RESET);

  /* EXTI interrupt init*/
  HAL_NVIC_SetPriority(EXTI0_IRQn, 0, 0);
  HAL_NVIC_EnableIRQ(EXTI0_IRQn);

  HAL_NVIC_SetPriority(EXTI1_IRQn, 0, 0);
  HAL_NVIC_EnableIRQ(EXTI1_IRQn);

  HAL_NVIC_SetPriority(EXTI2_IRQn, 0, 0);
  HAL_NVIC_EnableIRQ(EXTI2_IRQn);

  HAL_NVIC_SetPriority(EXTI3_IRQn, 0, 0);
  HAL_NVIC_EnableIRQ(EXTI3_IRQn);

  HAL_NVIC_SetPriority(EXTI4_IRQn, 0, 0);
  HAL_NVIC_EnableIRQ(EXTI4_IRQn);

  HAL_NVIC_SetPriority(EXTI15_10_IRQn, 2, 0);
  HAL_NVIC_EnableIRQ(EXTI15_10_IRQn);

}

/* USER CODE BEGIN 4 */
void drawCircle(void){
	i=5;
	while( i<30){
		LCD_DrawCircle(posX,posY,i);
		i++;
	}
}
void draw_mole(int offsetx,int offsety,uint8_t sizeX,uint16_t sizeY){

     for(int i=0;i<sizeY*3;i = i+3){
	     for(int j=0;j<sizeX*3;j= j+3){
			  draw(j+offsetx-30,i+offsety-30,molepic[j/3][i/3],3);

		 }
 }
}
void draw_clear(int offsetx, int offsety,uint8_t sizeX,uint16_t sizeY){

     for(int i=0;i<sizeY*3;i = i+3){
	     for(int j=0;j<sizeX*3;j= j+3){
			  draw(j+offsetx-30,i+offsety-30,0x0000,3);

		 }
 }
}
void draw_title(int offsetx,int offsety,uint8_t sizeX,uint16_t sizeY){

     for(int i=0;i<sizeY*10;i = i+10){
	     for(int j=0;j<sizeX*10;j= j+10){
			  draw(j+offsetx,i+offsety,title[j/10][i/10],10);

		 }
 }
}
void draw_moleDie(int offsetx,int offsety,uint8_t sizeX,uint16_t sizeY){

     for(int i=0;i<sizeY*3;i = i+3){
	     for(int j=0;j<sizeX*3;j= j+3){
			  draw(j+offsetx-30,i+offsety-30,moleDie[j/3][i/3],3);

		 }
 }
}
void draw_background(int offsetx,int offsety,uint8_t sizeX,uint16_t sizeY){

     for(int i=0;i<sizeY*5;i = i+5){
	     for(int j=0;j<sizeX*5;j= j+5){
			  draw(j+offsetx,i+offsety,background[j/5][i/5],5);
		 }
 }
}
void draw_hole(int offsetx,int offsety,uint8_t sizeX,uint16_t sizeY){

     for(int i=0;i<sizeY*3;i = i+3){
	     for(int j=0;j<sizeX*3;j= j+3){
			  draw(j+offsetx-36,i+offsety-36,hole[j/3][i/3],3);

		 }
 }
}
void control(){

   	if( isPress[0] == 1  && locationAvailable[0]  ){

	         draw_moleDie(locationX[0],locationY[0],15,15);
			     mole[0] = 0;
			     locationAvailable[0] = false;
			     draw_hole(locationX[0],locationY[0],19,19);
			     isPress[0] = 0;
				   score++;

		}

		if( isPress[1] == 1  && locationAvailable[1]   ){

			     draw_moleDie(locationX[1],locationY[1],15,15);
			     mole[1] = 0;
			     locationAvailable[1] = false;
			     draw_hole(locationX[1],locationY[1],19,19);
		     	 isPress[1] = 0;
			     score++;

		}

		if( isPress[2] == 1  && locationAvailable[2]   ){

			     draw_moleDie(locationX[2],locationY[2],15,15);
			     mole[2] = 0;
			     locationAvailable[2] = false;
			     draw_hole(locationX[2],locationY[2],19,19);
			     isPress[2] = 0;
		     	 score++;

		}

		if( isPress[3] == 1  && locationAvailable[3]  ){

			     draw_moleDie(locationX[3],locationY[3],15,15);
			     mole[3] = 0;
			     locationAvailable[3] = false;
			     draw_hole(locationX[3],locationY[3],19,19);
			     isPress[3] = 0;
			     score++;

		}

		if( isPress[4] == 1 && locationAvailable[4]   ){

			     draw_moleDie(locationX[4],locationY[4],15,15);
			     mole[4] = 0;
			     locationAvailable[4] = false;
			     draw_hole(locationX[4],locationY[4],19,19);
			     isPress[4] = 0;
			     score++;

		}

}

void hole_init(){

     draw_hole(locationX[0],locationY[0],19,19);
	   draw_hole(locationX[1],locationY[1],19,19);
	   draw_hole(locationX[2],locationY[2],19,19);
	   draw_hole(locationX[3],locationY[3],19,19);
	   draw_hole(locationX[4],locationY[4],19,19);

}
void hue_draw(){

 	draw(0,0,0xE228);
	draw(0,60,0xC145);
	draw(0,120,0x6137);
	draw(0,180,0x4052);
	draw(64,0,0x40EA);
	draw(64,60,0x3855);
	draw(64,120,0x61BB);
	draw(64,180,0x34BB);
	draw(128,0,0x0BD9);
	draw(128,60,0x05B5);
	draw(128,120,0x05AC);
	draw(128,180,0x0469);
	draw(192,0,0x0460);
	draw(192,60,0x57EA);
	draw(192,120,0xD6A3);
	draw(192,180,0xBD41);
	draw(256,0,0xB845);
	draw(256,60,0xEA60);
	draw(256,120,0xB2C5);
	draw(256,180,0x060C);

}
void gameplay(){

	   if(mole[0] == 0){                                  // mole number 1

			   temptimeshow[0] = rand()%2000+1000;
			   timeshow[0] = 0;
			   locationMole[0] = rand()%5;
			   while( locationAvailable[locationMole[0]]){
					     if(locationMole[0]==5)locationMole[0]=0;
					     locationMole[0]++;
			   }
				 locationAvailable[locationMole[0]] = true;
			   draw_mole(locationX[locationMole[0]],locationY[locationMole[0]],15,15);
			   mole[0] = 1;
		 }
		 if(timeshow[0] >= temptimeshow[0]){

		     mole[0] = 0 ;
			   locationAvailable[locationMole[0]] = false;
			   draw_hole(locationX[locationMole[0]],locationY[locationMole[0]],19,19);

		 }

     control();
		 sprintf(str, "score:%d time :%d  ",score,gametime);
		 LCD_DisplayStringLine(Line8,str);

		 if(mole[1] == 0){                                    // mole number 2

			   temptimeshow[1] = rand()%2000+1000;
			   timeshow[1] = 0;
			   locationMole[1] = rand()%5;
			   while( locationAvailable[locationMole[1]]){
					     if(locationMole[1]==5)locationMole[1]=0;
					     locationMole[1]++;
			   }
				 locationAvailable[locationMole[1]] = true;
			   draw_mole(locationX[locationMole[1]],locationY[locationMole[1]],15,15);
			   mole[1] = 1;
		 }
		 if(timeshow[1] >= temptimeshow[1]){

		     mole[1] = 0 ;
			   locationAvailable[locationMole[1]] = false;
			   draw_hole(locationX[locationMole[1]],locationY[locationMole[1]],19,19);
		 }

		 control();
		 sprintf(str, "score:%d time :%d  ",score,gametime);
		 LCD_DisplayStringLine(Line8,str);

		  if(mole[2] == 0){                                  // mole number 3

			   temptimeshow[2] = rand()%2000+1000;
			   timeshow[2] = 0;
			   locationMole[2] = rand()%5;
			   while( locationAvailable[locationMole[2]]){
					     if(locationMole[2]==5)locationMole[2]=0;
					     locationMole[2]++;
			   }
				 locationAvailable[locationMole[2]] = true;
			   draw_mole(locationX[locationMole[2]],locationY[locationMole[2]],15,15);
			   mole[2] = 1;
		 }
		 if(timeshow[2] >= temptimeshow[2]){

		     mole[2] = 0 ;
			   locationAvailable[locationMole[2]] = false;
			   draw_hole(locationX[locationMole[2]],locationY[locationMole[2]],19,19);
		 }
     control();
		 sprintf(str, "score:%d time :%d  ",score,gametime);
		 LCD_DisplayStringLine(Line8,str);

}
void gameover(){

	LCD_SetTextColor(White);
	LCD_SetBackColor(Black);
	sprintf(str, "     score :%d ",score);
	LCD_DisplayStringLine(Line4,"     Game Over !!");
	LCD_DisplayStringLine(Line5,str);

}

/* USER CODE END 4 */

void Error_Handler(void)
{
  while(1)
  {
  }
}

/************************ (C) COPYRIGHT STMicroelectronics *****END OF FILE****/
